AUTOSAR XML (schema 4-2-1)
package /ComponentTypes
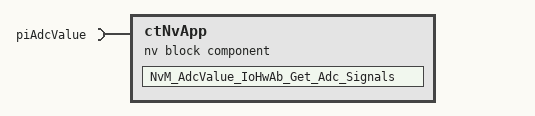
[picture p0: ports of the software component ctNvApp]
  nv block sw component type ctNvApp
    require port piAdcValue: nv-require-com-spec{init-value=255, variable=deAdcValue}, required-interface=piAdcValue
    behavior ctNvApp_InternalBehavior
      data received event DRT_NvM_AdcValue_IoHwAb_Get_Adc_Signals_piAdcValue_deAdcValue: start-on-event=NvM_AdcValue_IoHwAb_Get_Adc_Signals, data=piAdcValue.deAdcValue
      runnable NvM_AdcValue_IoHwAb_Get_Adc_Signals
    nv block descriptor NVBlock_AdcValue: nv-block-data-mapping{nv-ram-block-element=RAM_NVBlock_AdcValue, written-nv-data=piAdcValue.deAdcValue}, support-dirty-flag=true
      nv block needs NVNeed_NVBlock_AdcValue: calc-ram-block-crc=false, check-static-block-id=false, n-data-sets=0, ram-block-status-control=API, readonly=false, reliability=NO-PROTECTION, resistant-to-changed-sw=true, restore-at-start=true, store-at-shutdown=false, store-cyclic=false, store-emergency=false, store-immediate=true, use-auto-validation-at-shut-down=false, use-crc-comp-mechanism=false, write-only-once=false, write-verification=true, writing-priority=LOW
      ram block RAM_NVBlock_AdcValue: type=uint16, init-value=0
  swc implementation ctNvApp_Implementation: behavior=ctNvApp_InternalBehavior
    code-descriptors:
      code Default: artifact-descriptors=autosar-engineering-object={short-label=Default, category=SWSRC}
